# AM13E23019 register map
Vendor: Texas Instruments; File version: 1.0
CPU: CM33 r0p1, little endian, MPU, FPU, VTOR, 4 interrupt priority bits
Registers are 32-bit, read-write, reset 0x0 unless marked. A register's access mark holds for its fields unless they carry their own. Offsets are from the block's base; [hi:lo] are bit positions; {n}, {i} and the like mark numbered series; 'fields as' and 'values as' point back to an identical list.

## CMPSS0 — CMPSS_LITE module
Base 0x40460000
Same registers: CMPSS1 0x40461000, CMPSS2 0x40462000, CMPSS3 0x40463000
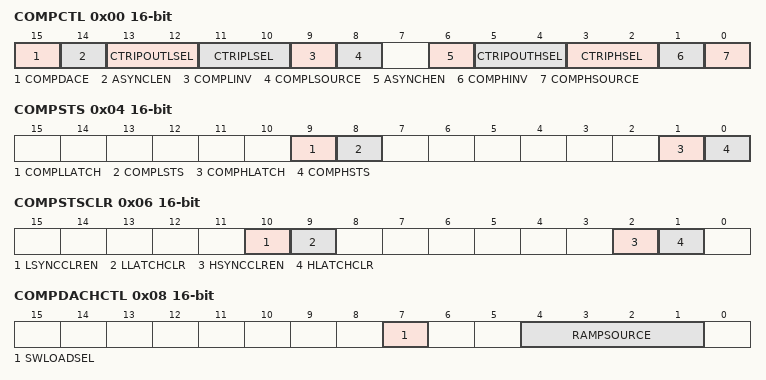
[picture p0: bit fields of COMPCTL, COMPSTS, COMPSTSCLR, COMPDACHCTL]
0x00 COMPCTL 16-bit — CMPSS Comparator Control Register
  [15] COMPDACE — Comparator/DAC Enable
  [14] ASYNCLEN — Low Comparator Asynchronous Path Enable
  [13:12] CTRIPOUTLSEL — Low Comparator Trip Output Select
  [11:10] CTRIPLSEL — Low Comparator Trip Select
  [9] COMPLINV — Low Comparator Invert Select
  [8] COMPLSOURCE — Low Comparator Source Select
  [6] ASYNCHEN — High Comparator Asynchronous Path Enable
  [5:4] CTRIPOUTHSEL — High Comparator Trip Output Select
  [3:2] CTRIPHSEL — High Comparator Trip Select
  [1] COMPHINV — High Comparator Invert Select
  [0] COMPHSOURCE — High Comparator Source Select
0x02 COMPHYSCTL 16-bit — CMPSS Comparator Hysteresis Control Register
  [3:0] COMPHYS — Comparator Hysteresis Trim
0x04 COMPSTS 16-bit ro — CMPSS Comparator Status Register
  [9] COMPLLATCH — Low Comparator Latched Status
  [8] COMPLSTS — Low Comparator Status
  [1] COMPHLATCH — High Comparator Latched Status
  [0] COMPHSTS — High Comparator Status
0x06 COMPSTSCLR 16-bit — CMPSS Comparator Status Clear Register
  [10] LSYNCCLREN — Low Comparator EPWMSYNCPER Clear Enable
  [9] LLATCHCLR — Low Comparator Latched Status Clear
  [2] HSYNCCLREN — High Comparator EPWMSYNCPER Clear Enable
  [1] HLATCHCLR — High Comparator Latched Status Clear
0x08 COMPDACHCTL 16-bit — CMPSS High DAC Control Register
  [7] SWLOADSEL — Software Load Select
  [4:1] RAMPSOURCE — Ramp Generator Source Control
0x0C DACHVALS 16-bit — CMPSS High DAC Value Shadow Register
  [11:0] DACVAL — DAC Value Control
0x0E DACHVALA 16-bit ro — CMPSS High DAC Value Active Register
  [11:0] DACVAL — DAC Value Control
0x24 DACLVALS 16-bit — CMPSS Low DAC Value Shadow Register
  [11:0] DACVAL — DAC Value Control
0x26 DACLVALA 16-bit ro — CMPSS Low DAC Value Active Register
  [11:0] DACVAL — DAC Value Control
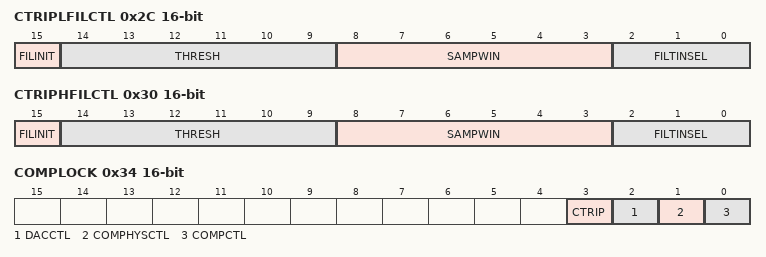
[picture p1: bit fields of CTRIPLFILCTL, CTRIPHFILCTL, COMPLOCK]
0x2C CTRIPLFILCTL 16-bit — CTRIPL Filter Control Register
  [15] FILINIT — Filter Initialization Bit
  [14:9] THRESH — Majority Voting Threshold
  [8:3] SAMPWIN — Sample Window
  [2:0] FILTINSEL — Filter Input Select
0x2E CTRIPLFILCLKCTL 16-bit access not given — CTRIPL Filter Clock Control Register
0x30 CTRIPHFILCTL 16-bit — CTRIPH Filter Control Register
  fields as CTRIPLFILCTL
0x32 CTRIPHFILCLKCTL 16-bit access not given — CTRIPH Filter Clock Control Register
0x34 COMPLOCK 16-bit — CMPSS Lock Register
  [3] CTRIP — CTRIP Lock
  [2] DACCTL — DACCTL Lock
  [1] COMPHYSCTL — COMPHYSCTL Lock
  [0] COMPCTL — COMPCTL Lock
0x48 COMPDACLCTL 16-bit — CMPSS Low DAC Control Register
  [4:1] RAMPSOURCE — Ramp Generator Source Control
0x6E CTRIPLFILCLKCTL2 16-bit — CTRIPL Filter Clock Control Register 2
  [7:0] CLKPRESCALEU — Sample Clock Prescale Upper Bits
0x72 CTRIPHFILCLKCTL2 16-bit — CTRIPH Filter Clock Control Register 2
  [7:0] CLKPRESCALEU — Sample Clock Prescale Upper Bits

## INPUTXBAR — INPUT_XBAR module
Base 0x40468000
{0x0+4i} INPUTSELECT[{i}] (i=0..27) — Input Select Register (GPIO0 to x)
  [7:0] SELECT — Select GPIO for INPUT{#} signal
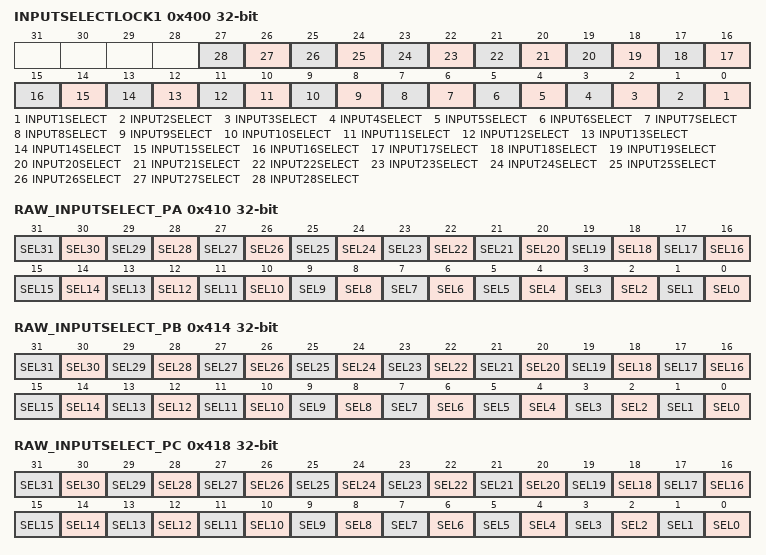
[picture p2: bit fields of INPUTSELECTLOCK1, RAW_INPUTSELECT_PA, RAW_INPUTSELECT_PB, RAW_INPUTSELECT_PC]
0x400 INPUTSELECTLOCK1 — Input Select Lock Register 1
  [n-1] INPUT{n}SELECT (n=1..28) — Lock bit for INPUT{n}SELECT Register
0x410 RAW_INPUTSELECT_PA — Raw Input Select Register for Port-A GPIOs
  [n] SEL{n} (n=0..31) — Raw input select bit for PA{n}
0x414 RAW_INPUTSELECT_PB — Raw Input Select Register for Port-B GPIOs
  [n] SEL{n} (n=0..31) — Raw input select bit for PB{n}
0x418 RAW_INPUTSELECT_PC — Raw Input Select Register for Port-C GPIOs
  [n] SEL{n} (n=0..31) — Raw input select bit for PC{n}
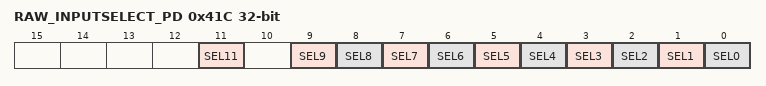
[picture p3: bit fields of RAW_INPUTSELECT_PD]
0x41C RAW_INPUTSELECT_PD — Raw Input Select Register for Port-D GPIOs
  [11] SEL11 — Raw input select bit for PD11
  [n] SEL{n} (n=0..9) — Raw input select bit for PD{n}
